# TM4C129ENCPDT register map
File version: 1.0
CPU: CORTEX_M4 1.0, other endian, MPU, FPU, 3 interrupt priority bits
Registers are 32-bit, read-write, reset 0x0 unless marked. A register's access mark holds for its fields unless they carry their own. Offsets are from the block's base; [hi:lo] are bit positions; {n}, {i} and the like mark numbered series.

## SHAMD5 — SHA/MD5 register offsets
Base 0x44034000
0x00 SHAMD5_ODIGEST_A — SHA Outer Digest A
  [31:0] SHAMD5_ODIGEST_A_DATA — [31:0] Digest/Key Data
0x04 SHAMD5_ODIGEST_B — SHA Outer Digest B
  [31:0] SHAMD5_ODIGEST_B_DATA — [31:0] Digest/Key Data
0x08 SHAMD5_ODIGEST_C — SHA Outer Digest C
  [31:0] SHAMD5_ODIGEST_C_DATA — [31:0] Digest/Key Data
0x0C SHAMD5_ODIGEST_D — SHA Outer Digest D
  [31:0] SHAMD5_ODIGEST_D_DATA — [31:0] Digest/Key Data
0x10 SHAMD5_ODIGEST_E — SHA Outer Digest E
  [31:0] SHAMD5_ODIGEST_E_DATA — [31:0] Digest/Key Data
0x14 SHAMD5_ODIGEST_F — SHA Outer Digest F
  [31:0] SHAMD5_ODIGEST_F_DATA — [31:0] Digest/Key Data
0x18 SHAMD5_ODIGEST_G — SHA Outer Digest G
  [31:0] SHAMD5_ODIGEST_G_DATA — [31:0] Digest/Key Data
0x1C SHAMD5_ODIGEST_H — SHA Outer Digest H
  [31:0] SHAMD5_ODIGEST_H_DATA — [31:0] Digest/Key Data
0x20 SHAMD5_IDIGEST_A — SHA Inner Digest A
  [31:0] SHAMD5_IDIGEST_A_DATA — [31:0] Digest/Key Data
0x24 SHAMD5_IDIGEST_B — SHA Inner Digest B
  [31:0] SHAMD5_IDIGEST_B_DATA — [31:0] Digest/Key Data
0x28 SHAMD5_IDIGEST_C — SHA Inner Digest C
  [31:0] SHAMD5_IDIGEST_C_DATA — [31:0] Digest/Key Data
0x2C SHAMD5_IDIGEST_D — SHA Inner Digest D
  [31:0] SHAMD5_IDIGEST_D_DATA — [31:0] Digest/Key Data
0x30 SHAMD5_IDIGEST_E — SHA Inner Digest E
  [31:0] SHAMD5_IDIGEST_E_DATA — [31:0] Digest/Key Data
0x34 SHAMD5_IDIGEST_F — SHA Inner Digest F
  [31:0] SHAMD5_IDIGEST_F_DATA — [31:0] Digest/Key Data
0x38 SHAMD5_IDIGEST_G — SHA Inner Digest G
  [31:0] SHAMD5_IDIGEST_G_DATA — [31:0] Digest/Key Data
0x3C SHAMD5_IDIGEST_H — SHA Inner Digest H
  [31:0] SHAMD5_IDIGEST_H_DATA — [31:0] Digest/Key Data
0x40 SHAMD5_DIGEST_COUNT — SHA Digest Count
  [31:0] SHAMD5_DIGEST_COUNT — [31:0] Digest Count
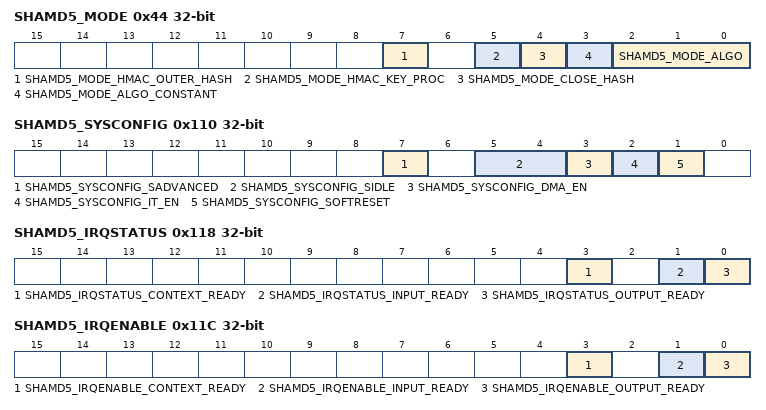
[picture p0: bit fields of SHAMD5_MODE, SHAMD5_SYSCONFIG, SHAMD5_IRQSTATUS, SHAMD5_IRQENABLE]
0x44 SHAMD5_MODE — SHA Mode
  [7] SHAMD5_MODE_HMAC_OUTER_HASH — [7:7] HMAC Outer Hash Processing Enable
  [5] SHAMD5_MODE_HMAC_KEY_PROC — [5:5] HMAC Key Processing Enable
  [4] SHAMD5_MODE_CLOSE_HASH — [4:4] Performs the padding, the Hash/HMAC will be 'closed' at the end of the block, as per MD5/SHA-1/SHA-2 specification
  [3] SHAMD5_MODE_ALGO_CONSTANT — [3:3] The initial digest register will be overwritten with the algorithm constants for the selected algorithm when hashing and the initial digest count register will be reset to 0
  [2:0] SHAMD5_MODE_ALGO — [2:0] Hash Algorithm
    0=SHAMD5_MODE_ALGO_MD5 (MD5); 2=SHAMD5_MODE_ALGO_SHA1 (SHA-1); 4=SHAMD5_MODE_ALGO_SHA224 (SHA-224); 6=SHAMD5_MODE_ALGO_SHA256 (SHA-256)
0x48 SHAMD5_LENGTH — SHA Length
  [31:0] SHAMD5_LENGTH — [31:0] Block Length/Remaining Byte Count
{0x80+4i} SHAMD5_DATA_{i}_IN (i=0..15) — SHA Data {i} Input
  [31:0] SHAMD5_DATA_{i}_IN_DATA — [31:0] Digest/Key Data
0x100 SHAMD5_REVISION — SHA Revision
  [31:0] SHAMD5_REVISION — [31:0] Revision Number
0x110 SHAMD5_SYSCONFIG — SHA System Configuration
  [7] SHAMD5_SYSCONFIG_SADVANCED — [7:7] Advanced Mode Enable
  [5:4] SHAMD5_SYSCONFIG_SIDLE — [5:4] Sidle mode
    0=SHAMD5_SYSCONFIG_SIDLE_FORCE (Force-idle mode)
  [3] SHAMD5_SYSCONFIG_DMA_EN — [3:3] uDMA Request Enable
  [2] SHAMD5_SYSCONFIG_IT_EN — [2:2] Interrupt Enable
  [1] SHAMD5_SYSCONFIG_SOFTRESET — [1:1] Soft reset
0x114 SHAMD5_SYSSTATUS — SHA System Status
  [0] SHAMD5_SYSSTATUS_RESETDONE — [0:0] Reset done status
0x118 SHAMD5_IRQSTATUS — SHA Interrupt Status
  [3] SHAMD5_IRQSTATUS_CONTEXT_READY — [3:3] Context Ready Status
  [1] SHAMD5_IRQSTATUS_INPUT_READY — [1:1] Input Ready Status
  [0] SHAMD5_IRQSTATUS_OUTPUT_READY — [0:0] Output Ready Status
0x11C SHAMD5_IRQENABLE — SHA Interrupt Enable
  [3] SHAMD5_IRQENABLE_CONTEXT_READY — [3:3] Mask for context ready interrupt
  [1] SHAMD5_IRQENABLE_INPUT_READY — [1:1] Mask for input ready interrupt
  [0] SHAMD5_IRQENABLE_OUTPUT_READY — [0:0] Mask for output ready interrupt
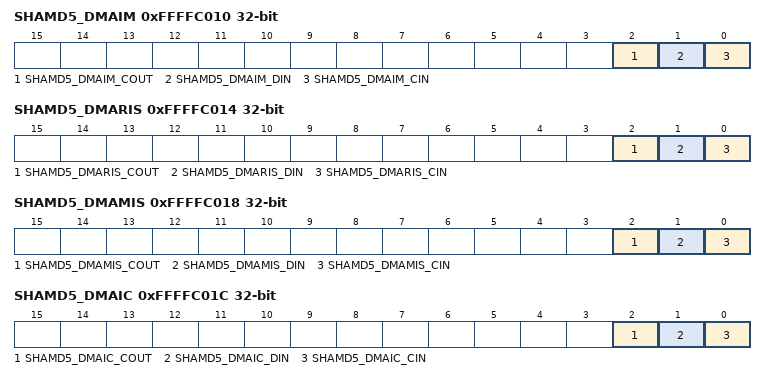
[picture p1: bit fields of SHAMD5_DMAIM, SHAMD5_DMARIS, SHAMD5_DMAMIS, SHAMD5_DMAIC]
0xFFFFC010 SHAMD5_DMAIM — SHA DMA Interrupt Mask
  [2] SHAMD5_DMAIM_COUT — [2:2] Context Out DMA Done Interrupt Mask
  [1] SHAMD5_DMAIM_DIN — [1:1] Data In DMA Done Interrupt Mask
  [0] SHAMD5_DMAIM_CIN — [0:0] Context In DMA Done Interrupt Mask
0xFFFFC014 SHAMD5_DMARIS — SHA DMA Raw Interrupt Status
  [2] SHAMD5_DMARIS_COUT — [2:2] Context Out DMA Done Raw Interrupt Status
  [1] SHAMD5_DMARIS_DIN — [1:1] Data In DMA Done Raw Interrupt Status
  [0] SHAMD5_DMARIS_CIN — [0:0] Context In DMA Done Raw Interrupt Status
0xFFFFC018 SHAMD5_DMAMIS — SHA DMA Masked Interrupt Status
  [2] SHAMD5_DMAMIS_COUT — [2:2] Context Out DMA Done Masked Interrupt Status
  [1] SHAMD5_DMAMIS_DIN — [1:1] Data In DMA Done Masked Interrupt Status
  [0] SHAMD5_DMAMIS_CIN — [0:0] Context In DMA Done Raw Interrupt Status
0xFFFFC01C SHAMD5_DMAIC — SHA DMA Interrupt Clear
  [2] SHAMD5_DMAIC_COUT — [2:2] Context Out DMA Done Masked Interrupt Status
  [1] SHAMD5_DMAIC_DIN — [1:1] Data In DMA Done Interrupt Clear
  [0] SHAMD5_DMAIC_CIN — [0:0] Context In DMA Done Raw Interrupt Status
